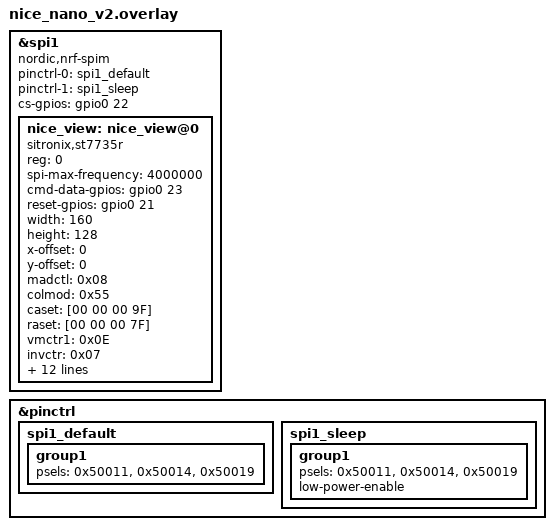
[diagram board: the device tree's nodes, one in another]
&spi1 {
    status = "okay";
    compatible = "nordic,nrf-spim";
    pinctrl-0 = <&spi1_default>;
    pinctrl-1 = <&spi1_sleep>;
    pinctrl-names = "default", "sleep";
    cs-gpios = <&gpio0 22 GPIO_ACTIVE_HIGH>;

    nice_view: nice_view@0 {
        compatible = "sitronix,st7735r";
        status = "okay";
        reg = <0>;
        spi-max-frequency = <4000000>;
        cmd-data-gpios = <&gpio0 23 GPIO_ACTIVE_HIGH>;
        reset-gpios = <&gpio0 21 GPIO_ACTIVE_HIGH>;
        width = <160>;
        height = <128>;
        x-offset = <0>;
        y-offset = <0>;
        madctl = <0x08>;
        colmod = <0x55>;
        caset = [00 00 00 9F];
        raset = [00 00 00 7F];
        vmctr1 = <0x0E>;
        invctr = <0x07>;
        pwctr1 = [A2 02 84];
        pwctr2 = [C5];
        pwctr3 = [0A 00];
        pwctr4 = [8A 2A];
        pwctr5 = [8A EE];
        frmctr1 = [01 2C 2D];
        frmctr2 = [01 2C 2D];
        frmctr3 = [01 2C 2D 01 2C 2D];
        gamctrp1 = [02 1C 07 12 37 32 29 2D 29 25 2B 39 00 01 03 10];
        gamctrn1 = [03 1D 07 06 2E 2C 29 2D 2E 2E 37 3F 00 00 02 10];
    };
};

&pinctrl {
    spi1_default: spi1_default {
        group1 {
            psels = <0x50011>,  /* MOSI on P0.17 */
                    <0x50014>,  /* SCK on P0.20 */
                    <0x50019>;  /* MISO on P0.25 */
        };
    };

    spi1_sleep: spi1_sleep {
        group1 {
            psels = <0x50011>,
                    <0x50014>,
                    <0x50019>;
            low-power-enable;
        };
    };
};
